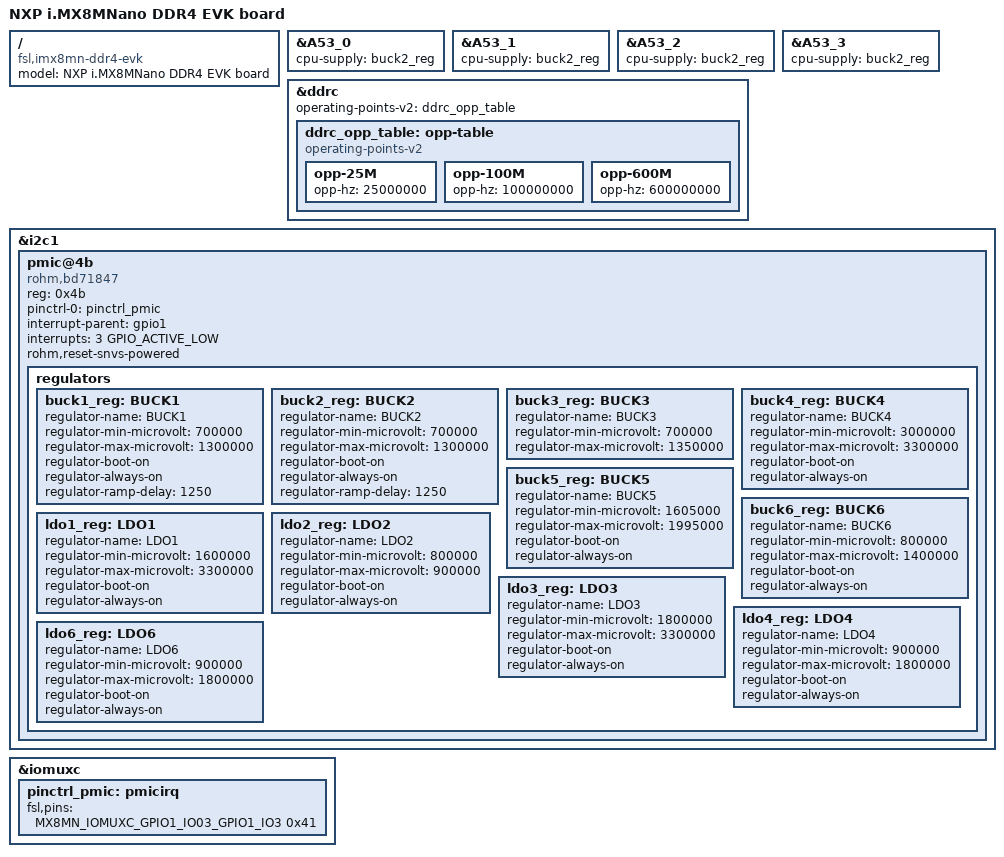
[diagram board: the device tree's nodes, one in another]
// SPDX-License-Identifier: (GPL-2.0+ OR MIT)
/*
 * Copyright 2019 NXP
 */

/dts-v1/;

#include "imx8mn.dtsi"
#include "imx8mn-evk.dtsi"

/ {
	model = "NXP i.MX8MNano DDR4 EVK board";
	compatible = "fsl,imx8mn-ddr4-evk", "fsl,imx8mn";
};

&A53_0 {
	cpu-supply = <&buck2_reg>;
};

&A53_1 {
	cpu-supply = <&buck2_reg>;
};

&A53_2 {
	cpu-supply = <&buck2_reg>;
};

&A53_3 {
	cpu-supply = <&buck2_reg>;
};

&ddrc {
	operating-points-v2 = <&ddrc_opp_table>;

	ddrc_opp_table: opp-table {
		compatible = "operating-points-v2";

		opp-25M {
			opp-hz = /bits/ 64 <25000000>;
		};

		opp-100M {
			opp-hz = /bits/ 64 <100000000>;
		};

		opp-600M {
			opp-hz = /bits/ 64 <600000000>;
		};
	};
};

&i2c1 {
	pmic@4b {
		compatible = "rohm,bd71847";
		reg = <0x4b>;
		pinctrl-0 = <&pinctrl_pmic>;
		interrupt-parent = <&gpio1>;
		interrupts = <3 GPIO_ACTIVE_LOW>;
		rohm,reset-snvs-powered;

		regulators {
			buck1_reg: BUCK1 {
				regulator-name = "BUCK1";
				regulator-min-microvolt = <700000>;
				regulator-max-microvolt = <1300000>;
				regulator-boot-on;
				regulator-always-on;
				regulator-ramp-delay = <1250>;
			};

			buck2_reg: BUCK2 {
				regulator-name = "BUCK2";
				regulator-min-microvolt = <700000>;
				regulator-max-microvolt = <1300000>;
				regulator-boot-on;
				regulator-always-on;
				regulator-ramp-delay = <1250>;
			};

			buck3_reg: BUCK3 {
				// BUCK5 in datasheet
				regulator-name = "BUCK3";
				regulator-min-microvolt = <700000>;
				regulator-max-microvolt = <1350000>;
			};

			buck4_reg: BUCK4 {
				// BUCK6 in datasheet
				regulator-name = "BUCK4";
				regulator-min-microvolt = <3000000>;
				regulator-max-microvolt = <3300000>;
				regulator-boot-on;
				regulator-always-on;
			};

			buck5_reg: BUCK5 {
				// BUCK7 in datasheet
				regulator-name = "BUCK5";
				regulator-min-microvolt = <1605000>;
				regulator-max-microvolt = <1995000>;
				regulator-boot-on;
				regulator-always-on;
			};

			buck6_reg: BUCK6 {
				// BUCK8 in datasheet
				regulator-name = "BUCK6";
				regulator-min-microvolt = <800000>;
				regulator-max-microvolt = <1400000>;
				regulator-boot-on;
				regulator-always-on;
			};

			ldo1_reg: LDO1 {
				regulator-name = "LDO1";
				regulator-min-microvolt = <1600000>;
				regulator-max-microvolt = <3300000>;
				regulator-boot-on;
				regulator-always-on;
			};

			ldo2_reg: LDO2 {
				regulator-name = "LDO2";
				regulator-min-microvolt = <800000>;
				regulator-max-microvolt = <900000>;
				regulator-boot-on;
				regulator-always-on;
			};

			ldo3_reg: LDO3 {
				regulator-name = "LDO3";
				regulator-min-microvolt = <1800000>;
				regulator-max-microvolt = <3300000>;
				regulator-boot-on;
				regulator-always-on;
			};

			ldo4_reg: LDO4 {
				regulator-name = "LDO4";
				regulator-min-microvolt = <900000>;
				regulator-max-microvolt = <1800000>;
				regulator-boot-on;
				regulator-always-on;
			};

			ldo6_reg: LDO6 {
				regulator-name = "LDO6";
				regulator-min-microvolt = <900000>;
				regulator-max-microvolt = <1800000>;
				regulator-boot-on;
				regulator-always-on;
			};
		};
	};
};

&iomuxc {
	pinctrl_pmic: pmicirq {
		fsl,pins = <
			MX8MN_IOMUXC_GPIO1_IO03_GPIO1_IO3	0x41
		>;
	};
};
